# STM32H7x5 register map
File version: 1.1
CPU: CM7 r0p0, little endian, no MPU, no FPU, 3 interrupt priority bits
Registers are 32-bit, read-write, reset 0x0 unless marked. A register's access mark holds for its fields unless they carry their own. Offsets are from the block's base; [hi:lo] are bit positions; {n}, {i} and the like mark numbered series.

## JPEG
Base 0x52003000
0x00 JPEG_CONFR0 wo — JPEG codec control register
  [0] START — Start This bit start or stop the encoding or decoding process. Read this register always return 0.
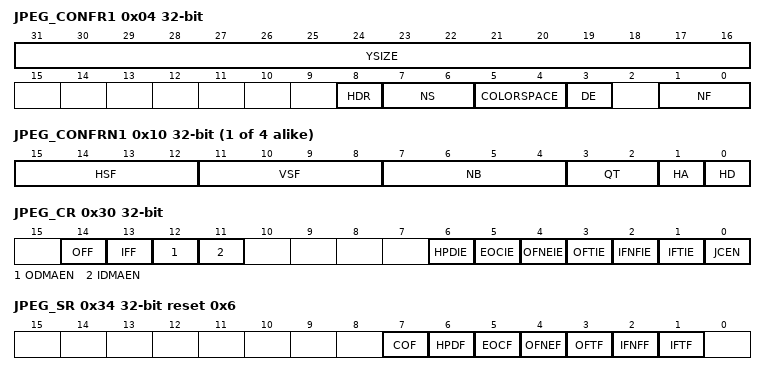
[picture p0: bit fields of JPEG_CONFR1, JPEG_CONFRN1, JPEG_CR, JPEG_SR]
0x04 JPEG_CONFR1 — JPEG codec configuration register 1
  [31:16] YSIZE — Y Size This field defines the number of lines in source image.
  [8] HDR — Header Processing This bit enable the header processing (generation/parsing).
  [7:6] NS — Number of components for Scan This field defines the number of components minus 1 for scan header marker segment.
  [5:4] COLORSPACE — Color Space This filed defines the number of quantization tables minus 1 to insert in the output stream.
  [3] DE — Decoding Enable This bit selects the coding or decoding process
  [1:0] NF — Number of color components This field defines the number of color components minus 1.
0x08 JPEG_CONFR2 — JPEG codec configuration register 2
  [25:0] NMCU — Number of MCU For encoding: this field defines the number of MCU units minus 1 to encode. For decoding: this field indicates the number of complete MCU units minus 1 to be decoded (this field is updated after the JPEG header parsing). If the decoded image size has not a X or Y size multiple of 8 or 16 (depending on the sub-sampling process), the resulting incomplete or empty MCU must be added to this value to get the total number of MCU generated.
0x0C JPEG_CONFR3 — JPEG codec configuration register 3
  [31:16] XSIZE — X size This field defines the number of pixels per line.
{0xC+4i} JPEG_CONFRN{i} (i=1..4) — JPEG codec configuration register 4-7
  [15:12] HSF — Horizontal Sampling Factor Horizontal sampling factor for component i.
  [11:8] VSF — Vertical Sampling Factor Vertical sampling factor for component i.
  [7:4] NB — Number of Block Number of data units minus 1 that belong to a particular color in the MCU.
  [3:2] QT — Quantization Table Selects quantization table associated with a color component.
  [1] HA — Huffman AC Selects the Huffman table for encoding the AC coefficients.
  [0] HD — Huffman DC Selects the Huffman table for encoding the DC coefficients.
0x30 JPEG_CR — JPEG control register
  [14] OFF — Output FIFO Flush This bit flush the output FIFO. This bit is always read as 0.
  [13] IFF — Input FIFO Flush This bit flush the input FIFO. This bit is always read as 0.
  [12] ODMAEN — Output DMA Enable Enable the DMA request generation for the output FIFO.
  [11] IDMAEN — Input DMA Enable Enable the DMA request generation for the input FIFO.
  [6] HPDIE — Header Parsing Done Interrupt Enable This bit enables the interrupt generation on the Header Parsing Operation.
  [5] EOCIE — End of Conversion Interrupt Enable This bit enables the interrupt generation on the end of conversion.
  [4] OFNEIE — Output FIFO Not Empty Interrupt Enable This bit enables the interrupt generation when output FIFO is not empty.
  [3] OFTIE — Output FIFO Threshold Interrupt Enable This bit enables the interrupt generation when output FIFO reach the threshold.
  [2] IFNFIE — Input FIFO Not Full Interrupt Enable This bit enables the interrupt generation when input FIFO is not empty.
  [1] IFTIE — Input FIFO Threshold Interrupt Enable This bit enables the interrupt generation when input FIFO reach the threshold.
  [0] JCEN — JPEG Core Enable Enable the JPEG codec Core.
0x34 JPEG_SR ro reset 0x6 — JPEG status register
  [7] COF — Codec Operation Flag This bit is set when when a JPEG codec operation is on going (encoding or decoding).
  [6] HPDF — Header Parsing Done Flag This bit is set in decode mode when the JPEG codec has finished the parsing of the headers and the internal registers have been updated.
  [5] EOCF — End of Conversion Flag This bit is set when the JPEG codec core has finished the encoding or the decoding process and than last data has been sent to the output FIFO.
  [4] OFNEF — Output FIFO Not Empty Flag This bit is set when the output FIFO is not empty (a data is available).
  [3] OFTF — Output FIFO Threshold Flag This bit is set when the output FIFO is not empty and has reach its threshold.
  [2] IFNFF — Input FIFO Not Full Flag This bit is set when the input FIFO is not full (a data can be written).
  [1] IFTF — Input FIFO Threshold Flag This bit is set when the input FIFO is not full and is bellow its threshold.
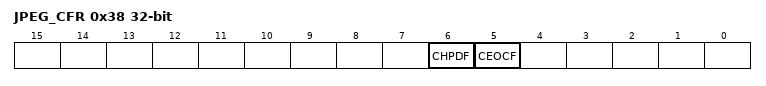
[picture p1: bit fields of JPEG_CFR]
0x38 JPEG_CFR — JPEG clear flag register
  [6] CHPDF — Clear Header Parsing Done Flag Writing 1 clears the Header Parsing Done Flag of the JPEG Status Register.
  [5] CEOCF — Clear End of Conversion Flag Writing 1 clears the End of Conversion Flag of the JPEG Status Register.
0x40 JPEG_DIR wo — JPEG data input register
  [31:0] DATAIN — Data Input FIFO Input FIFO data register.
0x44 JPEG_DOR ro — JPEG data output register
  [31:0] DATAOUT — Data Output FIFO Output FIFO data register.
